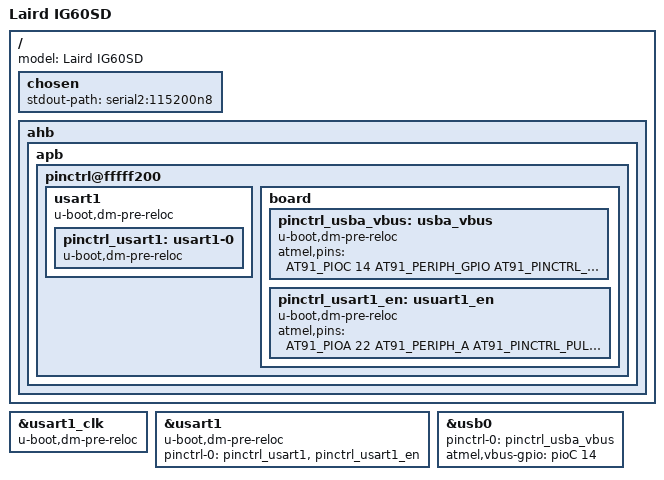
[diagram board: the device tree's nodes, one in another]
/*
 * at91-ig60sd.dts - Device Tree file for the IG60SD board
 *
 *  Copyright (C) 2019 Laird,
 *		  2019 Vishal Verma <vishal.verma@lairdconnect.com>
 *
 * Licensed under GPLv2 or later.
 */

/dts-v1/;

#include "at91-ig60.dts"

/ {
	model = "Laird IG60SD";
	chosen {
		stdout-path = "serial2:115200n8";
	};

	ahb {
		apb {

			pinctrl@fffff200 {
				usart1 {
					u-boot,dm-pre-reloc;
					pinctrl_usart1: usart1-0 {
						u-boot,dm-pre-reloc;
					};
				};

				board {
					pinctrl_usba_vbus: usba_vbus {
						u-boot,dm-pre-reloc;
						atmel,pins =
						<AT91_PIOC 14 AT91_PERIPH_GPIO AT91_PINCTRL_DEGLITCH>;
					};

					pinctrl_usart1_en: usuart1_en {
						u-boot,dm-pre-reloc;
						atmel,pins =
						<AT91_PIOA 22 AT91_PERIPH_A AT91_PINCTRL_PULL_UP
						AT91_PIOA 28 AT91_PERIPH_A AT91_PINCTRL_PULL_UP>;
					};
				};
			};
		};
	};
};

&usart1_clk {
	u-boot,dm-pre-reloc;
};

&usart1 {
	u-boot,dm-pre-reloc;
	pinctrl-names = "default";
	pinctrl-0 = <&pinctrl_usart1 &pinctrl_usart1_en>;
	status = "okay";
};

&usb0 {
	pinctrl-names = "default";
	pinctrl-0 = <&pinctrl_usba_vbus>;
	atmel,vbus-gpio = <&pioC 14 GPIO_ACTIVE_HIGH>;
	status = "okay";
};
